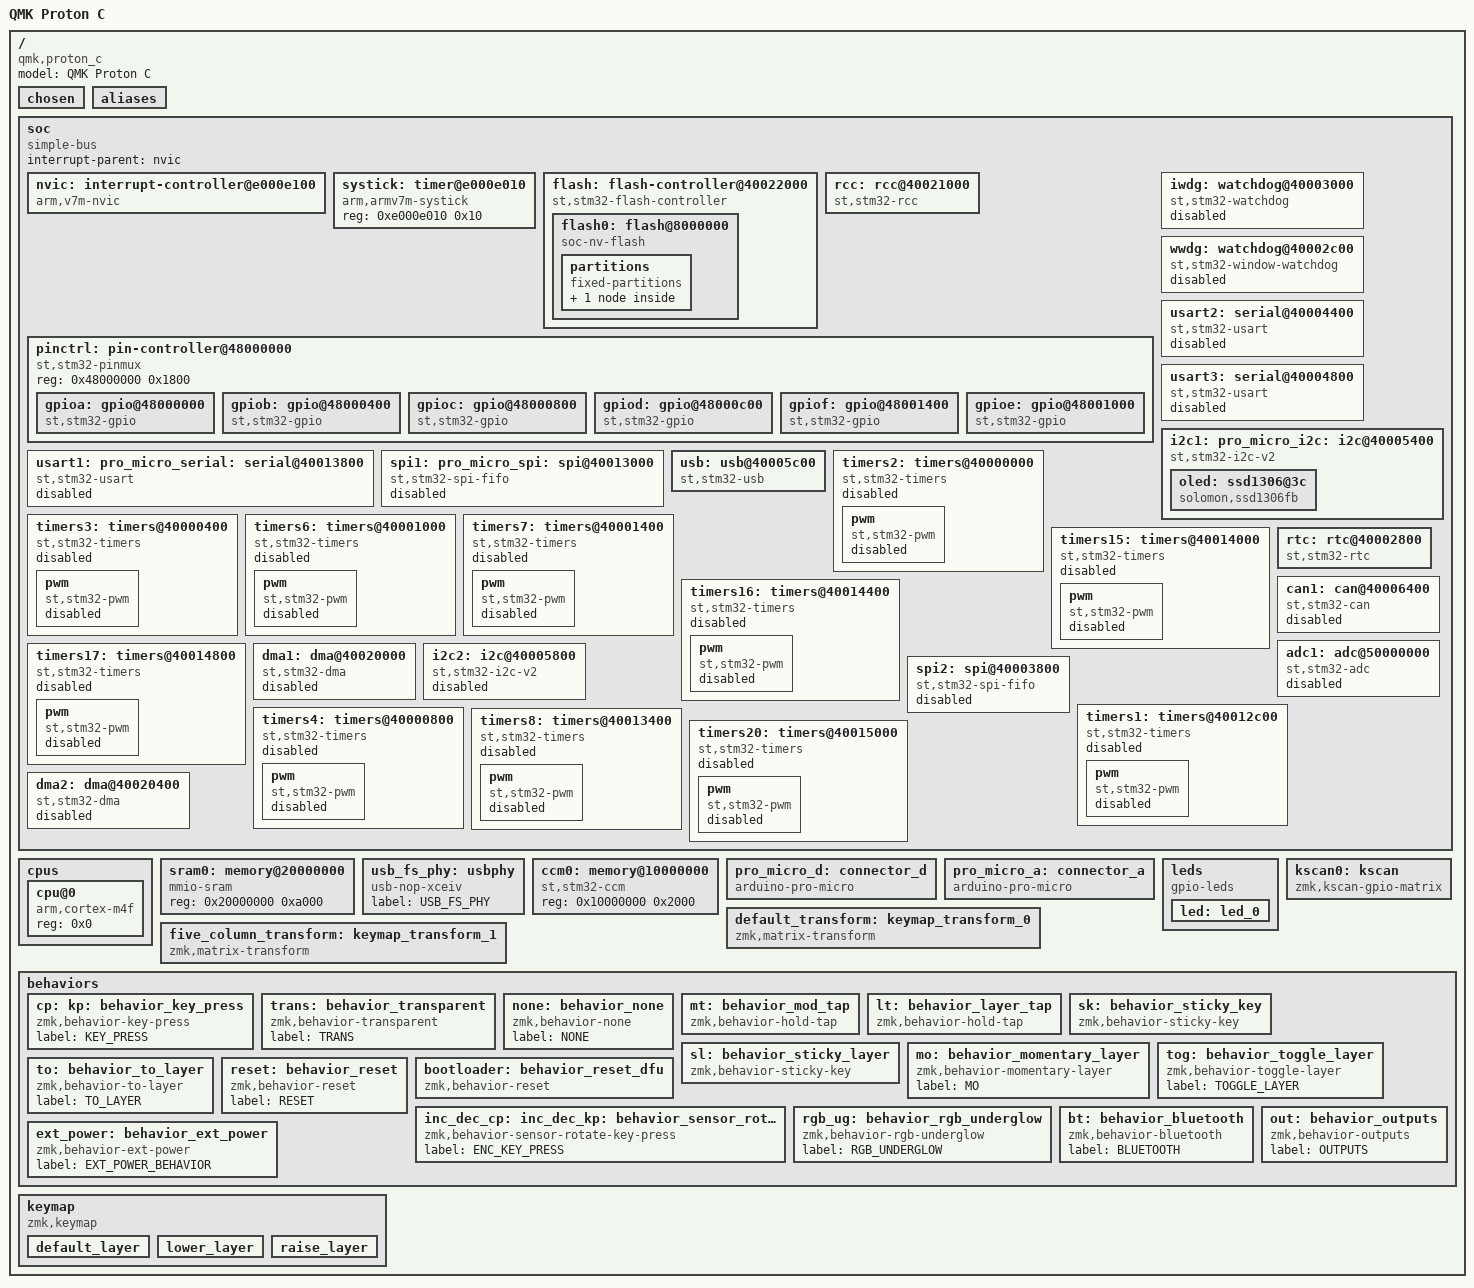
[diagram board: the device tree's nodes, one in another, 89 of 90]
/dts-v1/;

/ {
	#address-cells = < 0x1 >;
	#size-cells = < 0x1 >;
	model = "QMK Proton C";
	compatible = "qmk,proton_c", "st,stm32f303";
	chosen {
		zephyr,flash-controller = &flash;
		zephyr,sram = &sram0;
		zephyr,flash = &flash0;
		zmk,kscan = &kscan0;
		zmk,matrix_transform = &default_transform;
	};
	aliases {
	};
	soc {
		#address-cells = < 0x1 >;
		#size-cells = < 0x1 >;
		compatible = "simple-bus";
		interrupt-parent = < &nvic >;
		ranges;
		nvic: interrupt-controller@e000e100 {
			compatible = "arm,v7m-nvic";
			reg = < 0xe000e100 0xc00 >;
			interrupt-controller;
			#interrupt-cells = < 0x2 >;
			arm,num-irq-priority-bits = < 0x4 >;
			phandle = < 0x1 >;
		};
		systick: timer@e000e010 {
			compatible = "arm,armv7m-systick";
			reg = < 0xe000e010 0x10 >;
		};
		flash: flash-controller@40022000 {
			compatible = "st,stm32-flash-controller", "st,stm32f3-flash-controller";
			label = "FLASH_CTRL";
			reg = < 0x40022000 0x400 >;
			interrupts = < 0x4 0x0 >;
			#address-cells = < 0x1 >;
			#size-cells = < 0x1 >;
			flash0: flash@8000000 {
				compatible = "soc-nv-flash";
				label = "FLASH_STM32";
				write-block-size = < 0x2 >;
				erase-block-size = < 0x800 >;
				reg = < 0x8000000 0x40000 >;
				partitions {
					compatible = "fixed-partitions";
					#address-cells = < 0x1 >;
					#size-cells = < 0x1 >;
					storage_partition: partition@3e800 {
						label = "storage";
						reg = < 0x3e800 0x1800 >;
					};
				};
			};
		};
		rcc: rcc@40021000 {
			compatible = "st,stm32-rcc";
			#clock-cells = < 0x2 >;
			reg = < 0x40021000 0x400 >;
			label = "STM32_CLK_RCC";
			phandle = < 0x2 >;
		};
		pinctrl: pin-controller@48000000 {
			compatible = "st,stm32-pinmux";
			#address-cells = < 0x1 >;
			#size-cells = < 0x1 >;
			reg = < 0x48000000 0x1800 >;
			gpioa: gpio@48000000 {
				compatible = "st,stm32-gpio";
				gpio-controller;
				#gpio-cells = < 0x2 >;
				reg = < 0x48000000 0x400 >;
				clocks = < &rcc 0x0 0x20000 >;
				label = "GPIOA";
				phandle = < 0x4 >;
			};
			gpiob: gpio@48000400 {
				compatible = "st,stm32-gpio";
				gpio-controller;
				#gpio-cells = < 0x2 >;
				reg = < 0x48000400 0x400 >;
				clocks = < &rcc 0x0 0x40000 >;
				label = "GPIOB";
				phandle = < 0x5 >;
			};
			gpioc: gpio@48000800 {
				compatible = "st,stm32-gpio";
				gpio-controller;
				#gpio-cells = < 0x2 >;
				reg = < 0x48000800 0x400 >;
				clocks = < &rcc 0x0 0x80000 >;
				label = "GPIOC";
				phandle = < 0x6 >;
			};
			gpiod: gpio@48000c00 {
				compatible = "st,stm32-gpio";
				gpio-controller;
				#gpio-cells = < 0x2 >;
				reg = < 0x48000c00 0x400 >;
				clocks = < &rcc 0x0 0x100000 >;
				label = "GPIOD";
			};
			gpiof: gpio@48001400 {
				compatible = "st,stm32-gpio";
				gpio-controller;
				#gpio-cells = < 0x2 >;
				reg = < 0x48001400 0x400 >;
				clocks = < &rcc 0x0 0x400000 >;
				label = "GPIOF";
			};
			gpioe: gpio@48001000 {
				compatible = "st,stm32-gpio";
				gpio-controller;
				#gpio-cells = < 0x2 >;
				reg = < 0x48001000 0x400 >;
				clocks = < &rcc 0x0 0x200000 >;
				label = "GPIOE";
			};
		};
		iwdg: watchdog@40003000 {
			compatible = "st,stm32-watchdog";
			reg = < 0x40003000 0x400 >;
			label = "IWDG";
			status = "disabled";
		};
		wwdg: watchdog@40002c00 {
			compatible = "st,stm32-window-watchdog";
			reg = < 0x40002c00 0x400 >;
			clocks = < &rcc 0x2 0x800 >;
			label = "WWDG";
			interrupts = < 0x0 0x7 >;
			status = "disabled";
		};
		usart1: pro_micro_serial: serial@40013800 {
			compatible = "st,stm32-usart", "st,stm32-uart";
			reg = < 0x40013800 0x400 >;
			clocks = < &rcc 0x3 0x4000 >;
			interrupts = < 0x25 0x0 >;
			status = "disabled";
			label = "UART_1";
		};
		usart2: serial@40004400 {
			compatible = "st,stm32-usart", "st,stm32-uart";
			reg = < 0x40004400 0x400 >;
			clocks = < &rcc 0x2 0x20000 >;
			interrupts = < 0x26 0x0 >;
			status = "disabled";
			label = "UART_2";
		};
		usart3: serial@40004800 {
			compatible = "st,stm32-usart", "st,stm32-uart";
			reg = < 0x40004800 0x400 >;
			clocks = < &rcc 0x2 0x40000 >;
			interrupts = < 0x27 0x0 >;
			status = "disabled";
			label = "UART_3";
		};
		i2c1: pro_micro_i2c: i2c@40005400 {
			compatible = "st,stm32-i2c-v2";
			clock-frequency = < 0x186a0 >;
			#address-cells = < 0x1 >;
			#size-cells = < 0x0 >;
			reg = < 0x40005400 0x400 >;
			clocks = < &rcc 0x2 0x200000 >;
			interrupts = < 0x1f 0x0 >, < 0x20 0x0 >;
			interrupt-names = "event", "error";
			status = "okay";
			label = "I2C_1";
			oled: ssd1306@3c {
				compatible = "solomon,ssd1306fb";
				reg = < 0x3c >;
				label = "DISPLAY";
				width = < 0x80 >;
				height = < 0x20 >;
				segment-offset = < 0x0 >;
				page-offset = < 0x0 >;
				display-offset = < 0x0 >;
				multiplex-ratio = < 0x1f >;
				segment-remap;
				com-invdir;
				com-sequential;
				prechargep = < 0x22 >;
			};
		};
		spi1: pro_micro_spi: spi@40013000 {
			compatible = "st,stm32-spi-fifo", "st,stm32-spi";
			#address-cells = < 0x1 >;
			#size-cells = < 0x0 >;
			reg = < 0x40013000 0x400 >;
			clocks = < &rcc 0x3 0x1000 >;
			interrupts = < 0x23 0x5 >;
			status = "disabled";
			label = "SPI_1";
		};
		usb: usb@40005c00 {
			compatible = "st,stm32-usb";
			reg = < 0x40005c00 0x400 >;
			interrupts = < 0x4b 0x0 >;
			interrupt-names = "usb";
			num-bidir-endpoints = < 0x8 >;
			ram-size = < 0x200 >;
			phys = < &usb_fs_phy >;
			clocks = < &rcc 0x2 0x800000 >;
			status = "okay";
			label = "USB";
		};
		timers2: timers@40000000 {
			compatible = "st,stm32-timers";
			reg = < 0x40000000 0x400 >;
			clocks = < &rcc 0x2 0x1 >;
			interrupts = < 0x1c 0x0 >;
			interrupt-names = "global";
			status = "disabled";
			label = "TIMERS_2";
			pwm {
				compatible = "st,stm32-pwm";
				status = "disabled";
				st,prescaler = < 0x0 >;
				label = "PWM_2";
				#pwm-cells = < 0x3 >;
			};
		};
		timers3: timers@40000400 {
			compatible = "st,stm32-timers";
			reg = < 0x40000400 0x400 >;
			clocks = < &rcc 0x2 0x2 >;
			interrupts = < 0x1d 0x0 >;
			interrupt-names = "global";
			status = "disabled";
			label = "TIMERS_3";
			pwm {
				compatible = "st,stm32-pwm";
				status = "disabled";
				st,prescaler = < 0x2710 >;
				label = "PWM_3";
				#pwm-cells = < 0x3 >;
			};
		};
		timers6: timers@40001000 {
			compatible = "st,stm32-timers";
			reg = < 0x40001000 0x400 >;
			clocks = < &rcc 0x2 0x10 >;
			interrupts = < 0x36 0x0 >;
			interrupt-names = "global";
			status = "disabled";
			label = "TIMERS_6";
			pwm {
				compatible = "st,stm32-pwm";
				status = "disabled";
				st,prescaler = < 0x2710 >;
				label = "PWM_6";
				#pwm-cells = < 0x3 >;
			};
		};
		timers7: timers@40001400 {
			compatible = "st,stm32-timers";
			reg = < 0x40001400 0x400 >;
			clocks = < &rcc 0x2 0x20 >;
			interrupts = < 0x37 0x0 >;
			interrupt-names = "global";
			status = "disabled";
			label = "TIMERS_7";
			pwm {
				compatible = "st,stm32-pwm";
				status = "disabled";
				st,prescaler = < 0x2710 >;
				label = "PWM_7";
				#pwm-cells = < 0x3 >;
			};
		};
		timers15: timers@40014000 {
			compatible = "st,stm32-timers";
			reg = < 0x40014000 0x400 >;
			clocks = < &rcc 0x3 0x10000 >;
			interrupts = < 0x18 0x0 >;
			interrupt-names = "global";
			status = "disabled";
			label = "TIMERS_15";
			pwm {
				compatible = "st,stm32-pwm";
				status = "disabled";
				st,prescaler = < 0x2710 >;
				label = "PWM_15";
				#pwm-cells = < 0x3 >;
			};
		};
		timers16: timers@40014400 {
			compatible = "st,stm32-timers";
			reg = < 0x40014400 0x400 >;
			clocks = < &rcc 0x3 0x20000 >;
			interrupts = < 0x19 0x0 >;
			interrupt-names = "global";
			status = "disabled";
			label = "TIMERS_16";
			pwm {
				compatible = "st,stm32-pwm";
				status = "disabled";
				st,prescaler = < 0x2710 >;
				label = "PWM_16";
				#pwm-cells = < 0x3 >;
			};
		};
		timers17: timers@40014800 {
			compatible = "st,stm32-timers";
			reg = < 0x40014800 0x400 >;
			clocks = < &rcc 0x3 0x40000 >;
			interrupts = < 0x1a 0x0 >;
			interrupt-names = "global";
			status = "disabled";
			label = "TIMERS_17";
			pwm {
				compatible = "st,stm32-pwm";
				status = "disabled";
				st,prescaler = < 0x2710 >;
				label = "PWM_17";
				#pwm-cells = < 0x3 >;
			};
		};
		rtc: rtc@40002800 {
			compatible = "st,stm32-rtc";
			reg = < 0x40002800 0x400 >;
			clocks = < &rcc 0x2 0x10000000 >;
			interrupts = < 0x29 0x0 >;
			prescaler = < 0x8000 >;
			status = "okay";
			label = "RTC_0";
		};
		can1: can@40006400 {
			compatible = "st,stm32-can";
			#address-cells = < 0x1 >;
			#size-cells = < 0x0 >;
			reg = < 0x40006400 0x400 >;
			interrupts = < 0x13 0x0 >, < 0x14 0x0 >, < 0x15 0x0 >, < 0x16 0x0 >;
			interrupt-names = "TX", "RX0", "RX1", "SCE";
			clocks = < &rcc 0x2 0x2000000 >;
			status = "disabled";
			label = "CAN_1";
			bus-speed = < 0x1e848 >;
			sjw = < 0x1 >;
			prop-seg = < 0x0 >;
			phase-seg1 = < 0x5 >;
			phase-seg2 = < 0x6 >;
		};
		adc1: adc@50000000 {
			compatible = "st,stm32-adc";
			reg = < 0x50000000 0x400 >;
			clocks = < &rcc 0x0 0x10000000 >;
			interrupts = < 0x12 0x0 >;
			status = "disabled";
			label = "ADC_1";
			#io-channel-cells = < 0x1 >;
		};
		dma1: dma@40020000 {
			compatible = "st,stm32-dma";
			#dma-cells = < 0x4 >;
			reg = < 0x40020000 0x400 >;
			clocks = < &rcc 0x0 0x1 >;
			interrupts = < 0xb 0x0 0xc 0x0 0xd 0x0 0xe 0x0 0xf 0x0 0x10 0x0 0x11 0x0 >;
			status = "disabled";
			label = "DMA_1";
		};
		i2c2: i2c@40005800 {
			compatible = "st,stm32-i2c-v2";
			clock-frequency = < 0x186a0 >;
			#address-cells = < 0x1 >;
			#size-cells = < 0x0 >;
			reg = < 0x40005800 0x400 >;
			clocks = < &rcc 0x2 0x400000 >;
			interrupts = < 0x21 0x0 >, < 0x22 0x0 >;
			interrupt-names = "event", "error";
			status = "disabled";
			label = "I2C_2";
		};
		spi2: spi@40003800 {
			compatible = "st,stm32-spi-fifo", "st,stm32-spi";
			#address-cells = < 0x1 >;
			#size-cells = < 0x0 >;
			reg = < 0x40003800 0x400 >;
			clocks = < &rcc 0x2 0x4000 >;
			interrupts = < 0x24 0x5 >;
			status = "disabled";
			label = "SPI_2";
		};
		timers1: timers@40012c00 {
			compatible = "st,stm32-timers";
			reg = < 0x40012c00 0x400 >;
			clocks = < &rcc 0x3 0x800 >;
			interrupts = < 0x18 0x0 >, < 0x19 0x0 >, < 0x1a 0x0 >, < 0x1b 0x0 >;
			interrupt-names = "brk", "up", "trgcom", "cc";
			status = "disabled";
			label = "TIMERS_1";
			pwm {
				compatible = "st,stm32-pwm";
				status = "disabled";
				st,prescaler = < 0x2710 >;
				label = "PWM_1";
				#pwm-cells = < 0x3 >;
			};
		};
		timers4: timers@40000800 {
			compatible = "st,stm32-timers";
			reg = < 0x40000800 0x400 >;
			clocks = < &rcc 0x2 0x4 >;
			interrupts = < 0x1e 0x0 >;
			interrupt-names = "global";
			status = "disabled";
			label = "TIMERS_4";
			pwm {
				compatible = "st,stm32-pwm";
				status = "disabled";
				st,prescaler = < 0x2710 >;
				label = "PWM_4";
				#pwm-cells = < 0x3 >;
			};
		};
		timers8: timers@40013400 {
			compatible = "st,stm32-timers";
			reg = < 0x40013400 0x400 >;
			clocks = < &rcc 0x3 0x2000 >;
			interrupts = < 0x2b 0x0 >, < 0x2c 0x0 >, < 0x2d 0x0 >, < 0x2e 0x0 >;
			interrupt-names = "brk", "up", "trgcom", "cc";
			status = "disabled";
			label = "TIMERS_8";
			pwm {
				compatible = "st,stm32-pwm";
				status = "disabled";
				st,prescaler = < 0x2710 >;
				label = "PWM_8";
				#pwm-cells = < 0x3 >;
			};
		};
		timers20: timers@40015000 {
			compatible = "st,stm32-timers";
			reg = < 0x40015000 0x400 >;
			clocks = < &rcc 0x3 0x100000 >;
			interrupts = < 0x4d 0x0 >, < 0x4e 0x0 >, < 0x4f 0x0 >, < 0x50 0x0 >;
			interrupt-names = "brk", "up", "trgcom", "cc";
			status = "disabled";
			label = "TIMERS_20";
			pwm {
				compatible = "st,stm32-pwm";
				status = "disabled";
				st,prescaler = < 0x2710 >;
				label = "PWM_20";
				#pwm-cells = < 0x3 >;
			};
		};
		dma2: dma@40020400 {
			compatible = "st,stm32-dma";
			#dma-cells = < 0x4 >;
			reg = < 0x40020400 0x400 >;
			clocks = < &rcc 0x0 0x2 >;
			interrupts = < 0x38 0x0 0x39 0x0 0x3a 0x0 0x3b 0x0 0x3c 0x0 >;
			status = "disabled";
			label = "DMA_2";
		};
	};
	cpus {
		#address-cells = < 0x1 >;
		#size-cells = < 0x0 >;
		cpu@0 {
			device_type = "cpu";
			compatible = "arm,cortex-m4f";
			reg = < 0x0 >;
		};
	};
	sram0: memory@20000000 {
		compatible = "mmio-sram";
		reg = < 0x20000000 0xa000 >;
	};
	usb_fs_phy: usbphy {
		compatible = "usb-nop-xceiv";
		#phy-cells = < 0x0 >;
		label = "USB_FS_PHY";
		phandle = < 0x3 >;
	};
	ccm0: memory@10000000 {
		compatible = "st,stm32-ccm";
		reg = < 0x10000000 0x2000 >;
	};
	pro_micro_d: connector_d {
		compatible = "arduino-pro-micro";
		#gpio-cells = < 0x2 >;
		gpio-map-mask = < 0xffffffff 0xffffffc0 >;
		gpio-map-pass-thru = < 0x0 0x3f >;
		gpio-map = < 0x0 0x0 &gpioa 0xa 0x0 >, < 0x1 0x0 &gpioa 0x9 0x0 >, < 0x2 0x0 &gpiob 0x7 0x0 >, < 0x3 0x0 &gpiob 0x6 0x0 >, < 0x4 0x0 &gpiob 0x5 0x0 >, < 0x5 0x0 &gpiob 0x4 0x0 >, < 0x6 0x0 &gpiob 0x3 0x0 >, < 0x7 0x0 &gpiob 0x2 0x0 >, < 0x8 0x0 &gpiob 0x1 0x0 >, < 0x9 0x0 &gpiob 0x0 0x0 >, < 0xa 0x0 &gpiob 0x9 0x0 >, < 0x10 0x0 &gpiob 0xf 0x0 >, < 0xe 0x0 &gpiob 0xe 0x0 >, < 0xf 0x0 &gpiob 0xd 0x0 >;
		phandle = < 0x7 >;
	};
	pro_micro_a: connector_a {
		compatible = "arduino-pro-micro";
		#gpio-cells = < 0x2 >;
		gpio-map-mask = < 0xffffffff 0xffffffc0 >;
		gpio-map-pass-thru = < 0x0 0x3f >;
		gpio-map = < 0x0 0x0 &gpiob 0x8 0x0 >, < 0x1 0x0 &gpioa 0x0 0x0 >, < 0x2 0x0 &gpioa 0x1 0x0 >, < 0x3 0x0 &gpioa 0x2 0x0 >, < 0x6 0x0 &gpiob 0x5 0x0 >, < 0x7 0x0 &gpiob 0x3 0x0 >, < 0x8 0x0 &gpiob 0x1 0x0 >, < 0x9 0x0 &gpiob 0x0 0x0 >, < 0xa 0x0 &gpiob 0x9 0x0 >;
		phandle = < 0x8 >;
	};
	leds {
		compatible = "gpio-leds";
		led: led_0 {
			gpios = < &gpioc 0xd 0x0 >;
			label = "User LED";
		};
	};
	default_transform: keymap_transform_0 {
		compatible = "zmk,matrix-transform";
		columns = < 0xc >;
		rows = < 0x4 >;
		map = < 0x0 0x1 0x2 0x3 0x4 0x5 0x6 0x7 0x8 0x9 0xa 0xb 0x100 0x101 0x102 0x103 0x104 0x105 0x106 0x107 0x108 0x109 0x10a 0x10b 0x200 0x201 0x202 0x203 0x204 0x205 0x206 0x207 0x208 0x209 0x20a 0x20b 0x303 0x304 0x305 0x306 0x307 0x308 >;
		col-offset = < 0x6 >;
	};
	five_column_transform: keymap_transform_1 {
		compatible = "zmk,matrix-transform";
		columns = < 0xa >;
		rows = < 0x4 >;
		map = < 0x1 0x2 0x3 0x4 0x5 0x6 0x7 0x8 0x9 0xa 0x101 0x102 0x103 0x104 0x105 0x106 0x107 0x108 0x109 0x10a 0x201 0x202 0x203 0x204 0x205 0x206 0x207 0x208 0x209 0x20a 0x303 0x304 0x305 0x306 0x307 0x308 >;
	};
	kscan0: kscan {
		compatible = "zmk,kscan-gpio-matrix";
		label = "KSCAN";
		diode-direction = "col2row";
		row-gpios = < &pro_micro_d 0x4 0x20 >, < &pro_micro_d 0x5 0x20 >, < &pro_micro_d 0x6 0x20 >, < &pro_micro_d 0x7 0x20 >;
		col-gpios = < &pro_micro_d 0xe 0x0 >, < &pro_micro_d 0xf 0x0 >, < &pro_micro_a 0x0 0x0 >, < &pro_micro_a 0x1 0x0 >, < &pro_micro_a 0x2 0x0 >, < &pro_micro_a 0x3 0x0 >;
	};
	behaviors {
		cp: kp: behavior_key_press {
			compatible = "zmk,behavior-key-press";
			label = "KEY_PRESS";
			#binding-cells = < 0x1 >;
			phandle = < 0x9 >;
		};
		trans: behavior_transparent {
			compatible = "zmk,behavior-transparent";
			label = "TRANS";
			#binding-cells = < 0x0 >;
			phandle = < 0xc >;
		};
		none: behavior_none {
			compatible = "zmk,behavior-none";
			label = "NONE";
			#binding-cells = < 0x0 >;
		};
		mt: behavior_mod_tap {
			compatible = "zmk,behavior-hold-tap";
			label = "MOD_TAP";
			#binding-cells = < 0x2 >;
			flavor = "hold-preferred";
			tapping_term_ms = < 0xc8 >;
			bindings = < &kp >, < &kp >;
		};
		lt: behavior_layer_tap {
			compatible = "zmk,behavior-hold-tap";
			label = "LAYER_TAP";
			#binding-cells = < 0x2 >;
			flavor = "tap-preferred";
			tapping_term_ms = < 0xc8 >;
			bindings = < &mo >, < &kp >;
		};
		sk: behavior_sticky_key {
			compatible = "zmk,behavior-sticky-key";
			label = "STICKY_KEY";
			#binding-cells = < 0x1 >;
			release-after-ms = < 0x3e8 >;
			bindings = < &kp >;
		};
		sl: behavior_sticky_layer {
			compatible = "zmk,behavior-sticky-key";
			label = "STICKY_LAYER";
			#binding-cells = < 0x1 >;
			release-after-ms = < 0x3e8 >;
			bindings = < &mo >;
		};
		mo: behavior_momentary_layer {
			compatible = "zmk,behavior-momentary-layer";
			label = "MO";
			#binding-cells = < 0x1 >;
			phandle = < 0xa >;
		};
		tog: behavior_toggle_layer {
			compatible = "zmk,behavior-toggle-layer";
			label = "TOGGLE_LAYER";
			#binding-cells = < 0x1 >;
		};
		to: behavior_to_layer {
			compatible = "zmk,behavior-to-layer";
			label = "TO_LAYER";
			#binding-cells = < 0x1 >;
		};
		reset: behavior_reset {
			compatible = "zmk,behavior-reset";
			label = "RESET";
			#binding-cells = < 0x0 >;
		};
		bootloader: behavior_reset_dfu {
			compatible = "zmk,behavior-reset";
			label = "BOOTLOADER_RESET";
			type = < 0x57 >;
			#binding-cells = < 0x0 >;
		};
		inc_dec_cp: inc_dec_kp: behavior_sensor_rotate_key_press {
			compatible = "zmk,behavior-sensor-rotate-key-press";
			label = "ENC_KEY_PRESS";
			#sensor-binding-cells = < 0x2 >;
		};
		rgb_ug: behavior_rgb_underglow {
			compatible = "zmk,behavior-rgb-underglow";
			label = "RGB_UNDERGLOW";
			#binding-cells = < 0x2 >;
		};
		bt: behavior_bluetooth {
			compatible = "zmk,behavior-bluetooth";
			label = "BLUETOOTH";
			#binding-cells = < 0x2 >;
			phandle = < 0xb >;
		};
		ext_power: behavior_ext_power {
			compatible = "zmk,behavior-ext-power";
			label = "EXT_POWER_BEHAVIOR";
			#binding-cells = < 0x1 >;
		};
		out: behavior_outputs {
			compatible = "zmk,behavior-outputs";
			label = "OUTPUTS";
			#binding-cells = < 0x1 >;
		};
	};
	keymap {
		compatible = "zmk,keymap";
		default_layer {
			bindings = < &kp 0x7002b &kp 0x70014 &kp 0x7001a &kp 0x70008 &kp 0x70015 &kp 0x70017 &kp 0x7001c &kp 0x70018 &kp 0x7000c &kp 0x70012 &kp 0x70013 &kp 0x7002a &kp 0x700e0 &kp 0x70004 &kp 0x70016 &kp 0x70007 &kp 0x70009 &kp 0x7000a &kp 0x7000b &kp 0x7000d &kp 0x7000e &kp 0x7000f &kp 0x70033 &kp 0x70034 &kp 0x700e1 &kp 0x7001d &kp 0x7001b &kp 0x70006 &kp 0x70019 &kp 0x70005 &kp 0x70011 &kp 0x70010 &kp 0x70036 &kp 0x70037 &kp 0x70038 &kp 0x700e5 &kp 0x700e3 &mo 0x1 &kp 0x7002c &kp 0x70028 &mo 0x2 &kp 0x700e6 >;
		};
		lower_layer {
			bindings = < &kp 0x70029 &kp 0x7001e &kp 0x7001f &kp 0x70020 &kp 0x70021 &kp 0x70022 &kp 0x70023 &kp 0x70024 &kp 0x70025 &kp 0x70026 &kp 0x70027 &kp 0x7002a &bt 0x0 0x0 &bt 0x3 0x0 &bt 0x3 0x1 &bt 0x3 0x2 &bt 0x3 0x3 &bt 0x3 0x4 &kp 0x70050 &kp 0x70051 &kp 0x70052 &kp 0x7004f &trans &trans &kp 0x700e1 &trans &trans &trans &trans &trans &trans &trans &trans &trans &trans &trans &kp 0x700e3 &trans &kp 0x7002c &kp 0x70028 &trans &kp 0x700e6 >;
		};
		raise_layer {
			bindings = < &kp 0x70029 &kp 0x207001e &kp 0x207001f &kp 0x2070020 &kp 0x2070021 &kp 0x2070022 &kp 0x2070023 &kp 0x2070024 &kp 0x70055 &kp 0x2070026 &kp 0x2070027 &kp 0x7002a &kp 0x700e0 &trans &trans &trans &trans &trans &kp 0x7002d &kp 0x7002e &kp 0x7002f &kp 0x70030 &kp 0x2070031 &kp 0x70035 &kp 0x700e1 &trans &trans &trans &trans &trans &trans &trans &trans &trans &kp 0x70031 &kp 0x2070035 &kp 0x700e3 &trans &kp 0x7002c &kp 0x70028 &trans &kp 0x700e6 >;
		};
	};
};
